# CTRL_MODULE_CORE register map
Vendor: Texas Instruments
Registers are 32-bit, access per field, reset 0x0 unless marked. A register's access mark holds for its fields unless they carry their own. Offsets are as the file gives them; [hi:lo] are bit positions; {n}, {i} and the like mark numbered series; 'fields as' and 'values as' point back to an identical list.

## CTRL_MODULE_CORE (part 8 of 12)
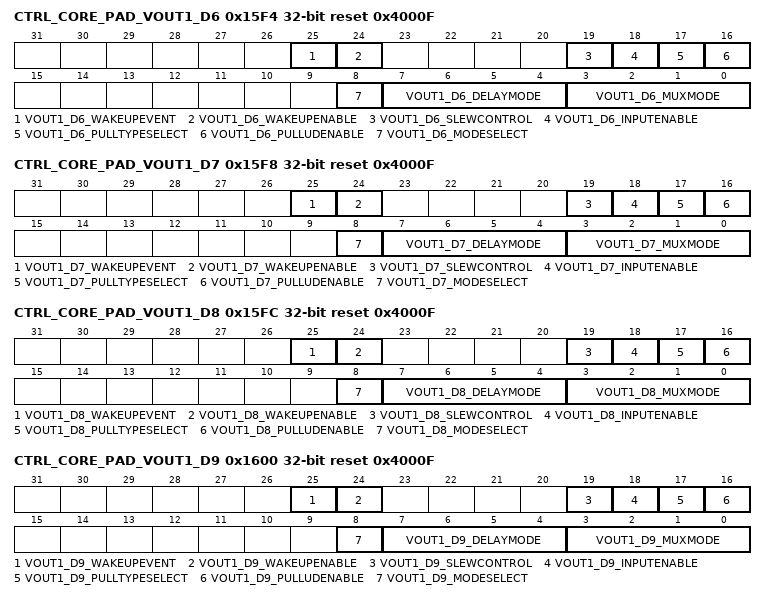
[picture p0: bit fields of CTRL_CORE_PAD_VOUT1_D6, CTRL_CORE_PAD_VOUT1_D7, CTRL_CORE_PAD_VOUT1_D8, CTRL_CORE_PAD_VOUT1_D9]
0x15F4 CTRL_CORE_PAD_VOUT1_D6 reset 0x4000F
  [25] VOUT1_D6_WAKEUPEVENT ro
    0=NOWAKEUP (No wakeup event detected); 1=WAKEUP (Wakeup event detected)
  [24] VOUT1_D6_WAKEUPENABLE rw
    0=DISABLE (Wakeup is disabled); 1=ENABLE (Wakeup is enabled)
  [19] VOUT1_D6_SLEWCONTROL rw
    0=FAST_SLEW (Fast slew is selected); 1=SLOW_SLEW (Slow slew is selected)
  [18] VOUT1_D6_INPUTENABLE rw
    0=DISABLE (Receive mode is disabled); 1=ENABLE (Receive mode is enabled)
  [17] VOUT1_D6_PULLTYPESELECT rw
    0=PULL_DOWN (Pull Down is selected); 1=PULL_UP (Pull Up is selected)
  [16] VOUT1_D6_PULLUDENABLE rw
    0=ENABLE (Enables weak Pull Up/Down); 1=DISABLE (Disables weak Pull Up/Down)
  [8] VOUT1_D6_MODESELECT rw — Selects between the Default IO Timing Mode and a Virtual or Manual IO Timing Mode. Refer to the device Data Manual for definition of the required settings for a given mode of operation. When this bit is 0b1, a Virtual IO Timing Mode can be selected via the DELAYMODE field of this register, as described in, Virtual IO Timing Modes. Manual IO Timing Modes are selected via the procedure described in , Manual IO Timing Modes.
    0=MUX_MODE (Default IO Timing Mode is used); 1=DELAY_MODE (A Virtual or Manual IO Timing Mode is used)
  [7:4] VOUT1_D6_DELAYMODE rw — This bit field selects the Virtual Timing Mode used when the MODESELECT bit is set to 0b1. See, Virtual IO Timing Modes for details.
  [3:0] VOUT1_D6_MUXMODE rw
    0=VOUT1_D6; 2=EMU8; 3=VIN4A_D22; 4=VIN3A_D22; 5=OBS4; 6=OBS20; 10=PR2_EDC_LATCH1_IN; 12=PR2_PRU0_GPI3; 13=PR2_PRU0_GPO3; 14=GPIO8_6; 15=DRIVER OFF
0x15F8 CTRL_CORE_PAD_VOUT1_D7 reset 0x4000F
  [25] VOUT1_D7_WAKEUPEVENT ro
    values as CTRL_CORE_PAD_VOUT1_D6.VOUT1_D6_WAKEUPEVENT
  [24] VOUT1_D7_WAKEUPENABLE rw
    0=DISABLE (Wakeup is disabled); 1=ENABLE (Wakeup is enabled)
  [19] VOUT1_D7_SLEWCONTROL rw
    values as CTRL_CORE_PAD_VOUT1_D6.VOUT1_D6_SLEWCONTROL
  [18] VOUT1_D7_INPUTENABLE rw
    values as CTRL_CORE_PAD_VOUT1_D6.VOUT1_D6_INPUTENABLE
  [17] VOUT1_D7_PULLTYPESELECT rw
    values as CTRL_CORE_PAD_VOUT1_D6.VOUT1_D6_PULLTYPESELECT
  [16] VOUT1_D7_PULLUDENABLE rw
    values as CTRL_CORE_PAD_VOUT1_D6.VOUT1_D6_PULLUDENABLE
  [8] VOUT1_D7_MODESELECT rw — Selects between the Default IO Timing Mode and a Virtual or Manual IO Timing Mode. Refer to the device Data Manual for definition of the required settings for a given mode of operation. When this bit is 0b1, a Virtual IO Timing Mode can be selected via the DELAYMODE field of this register, as described in, Virtual IO Timing Modes. Manual IO Timing Modes are selected via the procedure described in , Manual IO Timing Modes.
    values as CTRL_CORE_PAD_VOUT1_D6.VOUT1_D6_MODESELECT
  [7:4] VOUT1_D7_DELAYMODE rw — This bit field selects the Virtual Timing Mode used when the MODESELECT bit is set to 0b1. See, Virtual IO Timing Modes for details.
  [3:0] VOUT1_D7_MUXMODE rw
    0=VOUT1_D7; 2=EMU9; 3=VIN4A_D23; 4=VIN3A_D23; 10=PR2_EDC_SYNC0_OUT; 12=PR2_PRU0_GPI4; 13=PR2_PRU0_GPO4; 14=GPIO8_7; 15=DRIVER OFF
0x15FC CTRL_CORE_PAD_VOUT1_D8 reset 0x4000F
  [25] VOUT1_D8_WAKEUPEVENT ro
    values as CTRL_CORE_PAD_VOUT1_D6.VOUT1_D6_WAKEUPEVENT
  [24] VOUT1_D8_WAKEUPENABLE rw
    0=DISABLE (Wakeup is disabled); 1=ENABLE (Wakeup is enabled)
  [19] VOUT1_D8_SLEWCONTROL rw
    values as CTRL_CORE_PAD_VOUT1_D6.VOUT1_D6_SLEWCONTROL
  [18] VOUT1_D8_INPUTENABLE rw
    values as CTRL_CORE_PAD_VOUT1_D6.VOUT1_D6_INPUTENABLE
  [17] VOUT1_D8_PULLTYPESELECT rw
    values as CTRL_CORE_PAD_VOUT1_D6.VOUT1_D6_PULLTYPESELECT
  [16] VOUT1_D8_PULLUDENABLE rw
    values as CTRL_CORE_PAD_VOUT1_D6.VOUT1_D6_PULLUDENABLE
  [8] VOUT1_D8_MODESELECT rw — Selects between the Default IO Timing Mode and a Virtual or Manual IO Timing Mode. Refer to the device Data Manual for definition of the required settings for a given mode of operation. When this bit is 0b1, a Virtual IO Timing Mode can be selected via the DELAYMODE field of this register, as described in, Virtual IO Timing Modes. Manual IO Timing Modes are selected via the procedure described in , Manual IO Timing Modes.
    values as CTRL_CORE_PAD_VOUT1_D6.VOUT1_D6_MODESELECT
  [7:4] VOUT1_D8_DELAYMODE rw — This bit field selects the Virtual Timing Mode used when the MODESELECT bit is set to 0b1. See, Virtual IO Timing Modes for details.
  [3:0] VOUT1_D8_MUXMODE rw
    0=VOUT1_D8; 2=UART6_RXD; 3=VIN4A_D8; 4=VIN3A_D8; 10=PR2_EDC_SYNC1_OUT; 12=PR2_PRU0_GPI5; 13=PR2_PRU0_GPO5; 14=GPIO8_8; 15=DRIVER OFF
0x1600 CTRL_CORE_PAD_VOUT1_D9 reset 0x4000F
  [25] VOUT1_D9_WAKEUPEVENT ro
    values as CTRL_CORE_PAD_VOUT1_D6.VOUT1_D6_WAKEUPEVENT
  [24] VOUT1_D9_WAKEUPENABLE rw
    0=DISABLE (Wakeup is disabled); 1=ENABLE (Wakeup is enabled)
  [19] VOUT1_D9_SLEWCONTROL rw
    values as CTRL_CORE_PAD_VOUT1_D6.VOUT1_D6_SLEWCONTROL
  [18] VOUT1_D9_INPUTENABLE rw
    values as CTRL_CORE_PAD_VOUT1_D6.VOUT1_D6_INPUTENABLE
  [17] VOUT1_D9_PULLTYPESELECT rw
    values as CTRL_CORE_PAD_VOUT1_D6.VOUT1_D6_PULLTYPESELECT
  [16] VOUT1_D9_PULLUDENABLE rw
    values as CTRL_CORE_PAD_VOUT1_D6.VOUT1_D6_PULLUDENABLE
  [8] VOUT1_D9_MODESELECT rw — Selects between the Default IO Timing Mode and a Virtual or Manual IO Timing Mode. Refer to the device Data Manual for definition of the required settings for a given mode of operation. When this bit is 0b1, a Virtual IO Timing Mode can be selected via the DELAYMODE field of this register, as described in, Virtual IO Timing Modes. Manual IO Timing Modes are selected via the procedure described in , Manual IO Timing Modes.
    values as CTRL_CORE_PAD_VOUT1_D6.VOUT1_D6_MODESELECT
  [7:4] VOUT1_D9_DELAYMODE rw — This bit field selects the Virtual Timing Mode used when the MODESELECT bit is set to 0b1. See, Virtual IO Timing Modes for details.
  [3:0] VOUT1_D9_MUXMODE rw
    0=VOUT1_D9; 2=UART6_TXD; 3=VIN4A_D9; 4=VIN3A_D9; 10=PR2_EDIO_LATCH_IN; 12=PR2_PRU0_GPI6; 13=PR2_PRU0_GPO6; 14=GPIO8_9; 15=DRIVER OFF
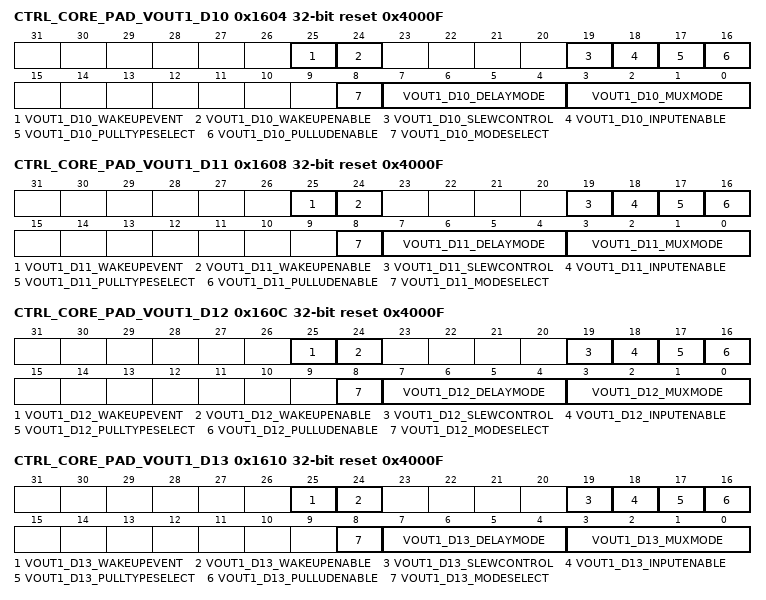
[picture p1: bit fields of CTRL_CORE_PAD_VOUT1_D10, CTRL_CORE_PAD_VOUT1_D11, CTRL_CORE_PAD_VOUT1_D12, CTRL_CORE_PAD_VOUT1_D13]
0x1604 CTRL_CORE_PAD_VOUT1_D10 reset 0x4000F
  [25] VOUT1_D10_WAKEUPEVENT ro
    values as CTRL_CORE_PAD_VOUT1_D6.VOUT1_D6_WAKEUPEVENT
  [24] VOUT1_D10_WAKEUPENABLE rw
    0=DISABLE (Wakeup is disabled); 1=ENABLE (Wakeup is enabled)
  [19] VOUT1_D10_SLEWCONTROL rw
    values as CTRL_CORE_PAD_VOUT1_D6.VOUT1_D6_SLEWCONTROL
  [18] VOUT1_D10_INPUTENABLE rw
    values as CTRL_CORE_PAD_VOUT1_D6.VOUT1_D6_INPUTENABLE
  [17] VOUT1_D10_PULLTYPESELECT rw
    values as CTRL_CORE_PAD_VOUT1_D6.VOUT1_D6_PULLTYPESELECT
  [16] VOUT1_D10_PULLUDENABLE rw
    values as CTRL_CORE_PAD_VOUT1_D6.VOUT1_D6_PULLUDENABLE
  [8] VOUT1_D10_MODESELECT rw — Selects between the Default IO Timing Mode and a Virtual or Manual IO Timing Mode. Refer to the device Data Manual for definition of the required settings for a given mode of operation. When this bit is 0b1, a Virtual IO Timing Mode can be selected via the DELAYMODE field of this register, as described in, Virtual IO Timing Modes. Manual IO Timing Modes are selected via the procedure described in , Manual IO Timing Modes.
    values as CTRL_CORE_PAD_VOUT1_D6.VOUT1_D6_MODESELECT
  [7:4] VOUT1_D10_DELAYMODE rw — This bit field selects the Virtual Timing Mode used when the MODESELECT bit is set to 0b1. See, Virtual IO Timing Modes for details.
  [3:0] VOUT1_D10_MUXMODE rw
    0=VOUT1_D10; 2=EMU3; 3=VIN4A_D10; 4=VIN3A_D10; 5=OBS5; 6=OBS21; 7=OBS_IRQ2; 10=PR2_EDIO_SOF; 12=PR2_PRU0_GPI7; 13=PR2_PRU0_GPO7; 14=GPIO8_10; 15=DRIVER OFF
0x1608 CTRL_CORE_PAD_VOUT1_D11 reset 0x4000F
  [25] VOUT1_D11_WAKEUPEVENT ro
    values as CTRL_CORE_PAD_VOUT1_D6.VOUT1_D6_WAKEUPEVENT
  [24] VOUT1_D11_WAKEUPENABLE rw
    0=DISABLE (Wakeup is disabled); 1=ENABLE (Wakeup is enabled)
  [19] VOUT1_D11_SLEWCONTROL rw
    values as CTRL_CORE_PAD_VOUT1_D6.VOUT1_D6_SLEWCONTROL
  [18] VOUT1_D11_INPUTENABLE rw
    values as CTRL_CORE_PAD_VOUT1_D6.VOUT1_D6_INPUTENABLE
  [17] VOUT1_D11_PULLTYPESELECT rw
    values as CTRL_CORE_PAD_VOUT1_D6.VOUT1_D6_PULLTYPESELECT
  [16] VOUT1_D11_PULLUDENABLE rw
    values as CTRL_CORE_PAD_VOUT1_D6.VOUT1_D6_PULLUDENABLE
  [8] VOUT1_D11_MODESELECT rw — Selects between the Default IO Timing Mode and a Virtual or Manual IO Timing Mode. Refer to the device Data Manual for definition of the required settings for a given mode of operation. When this bit is 0b1, a Virtual IO Timing Mode can be selected via the DELAYMODE field of this register, as described in, Virtual IO Timing Modes. Manual IO Timing Modes are selected via the procedure described in , Manual IO Timing Modes.
    values as CTRL_CORE_PAD_VOUT1_D6.VOUT1_D6_MODESELECT
  [7:4] VOUT1_D11_DELAYMODE rw — This bit field selects the Virtual Timing Mode used when the MODESELECT bit is set to 0b1. See, Virtual IO Timing Modes for details.
  [3:0] VOUT1_D11_MUXMODE rw
    0=VOUT1_D11; 2=EMU10; 3=VIN4A_D11; 4=VIN3A_D11; 5=OBS6; 6=OBS22; 7=OBS_DMARQ2; 10=PR2_UART0_CTS_N; 12=PR2_PRU0_GPI8; 13=PR2_PRU0_GPO8; 14=GPIO8_11; 15=DRIVER OFF
0x160C CTRL_CORE_PAD_VOUT1_D12 reset 0x4000F
  [25] VOUT1_D12_WAKEUPEVENT ro
    values as CTRL_CORE_PAD_VOUT1_D6.VOUT1_D6_WAKEUPEVENT
  [24] VOUT1_D12_WAKEUPENABLE rw
    0=DISABLE (Wakeup is disabled); 1=ENABLE (Wakeup is enabled)
  [19] VOUT1_D12_SLEWCONTROL rw
    values as CTRL_CORE_PAD_VOUT1_D6.VOUT1_D6_SLEWCONTROL
  [18] VOUT1_D12_INPUTENABLE rw
    values as CTRL_CORE_PAD_VOUT1_D6.VOUT1_D6_INPUTENABLE
  [17] VOUT1_D12_PULLTYPESELECT rw
    values as CTRL_CORE_PAD_VOUT1_D6.VOUT1_D6_PULLTYPESELECT
  [16] VOUT1_D12_PULLUDENABLE rw
    values as CTRL_CORE_PAD_VOUT1_D6.VOUT1_D6_PULLUDENABLE
  [8] VOUT1_D12_MODESELECT rw — Selects between the Default IO Timing Mode and a Virtual or Manual IO Timing Mode. Refer to the device Data Manual for definition of the required settings for a given mode of operation. When this bit is 0b1, a Virtual IO Timing Mode can be selected via the DELAYMODE field of this register, as described in, Virtual IO Timing Modes. Manual IO Timing Modes are selected via the procedure described in , Manual IO Timing Modes.
    values as CTRL_CORE_PAD_VOUT1_D6.VOUT1_D6_MODESELECT
  [7:4] VOUT1_D12_DELAYMODE rw — This bit field selects the Virtual Timing Mode used when the MODESELECT bit is set to 0b1. See, Virtual IO Timing Modes for details.
  [3:0] VOUT1_D12_MUXMODE rw
    0=VOUT1_D12; 2=EMU11; 3=VIN4A_D12; 4=VIN3A_D12; 5=OBS7; 6=OBS23; 10=PR2_UART0_RTS_N; 12=PR2_PRU0_GPI9; 13=PR2_PRU0_GPO9; 14=GPIO8_12; 15=DRIVER OFF
0x1610 CTRL_CORE_PAD_VOUT1_D13 reset 0x4000F
  [25] VOUT1_D13_WAKEUPEVENT ro
    values as CTRL_CORE_PAD_VOUT1_D6.VOUT1_D6_WAKEUPEVENT
  [24] VOUT1_D13_WAKEUPENABLE rw
    0=DISABLE (Wakeup is disabled); 1=ENABLE (Wakeup is enabled)
  [19] VOUT1_D13_SLEWCONTROL rw
    values as CTRL_CORE_PAD_VOUT1_D6.VOUT1_D6_SLEWCONTROL
  [18] VOUT1_D13_INPUTENABLE rw
    values as CTRL_CORE_PAD_VOUT1_D6.VOUT1_D6_INPUTENABLE
  [17] VOUT1_D13_PULLTYPESELECT rw
    values as CTRL_CORE_PAD_VOUT1_D6.VOUT1_D6_PULLTYPESELECT
  [16] VOUT1_D13_PULLUDENABLE rw
    values as CTRL_CORE_PAD_VOUT1_D6.VOUT1_D6_PULLUDENABLE
  [8] VOUT1_D13_MODESELECT rw — Selects between the Default IO Timing Mode and a Virtual or Manual IO Timing Mode. Refer to the device Data Manual for definition of the required settings for a given mode of operation. When this bit is 0b1, a Virtual IO Timing Mode can be selected via the DELAYMODE field of this register, as described in, Virtual IO Timing Modes. Manual IO Timing Modes are selected via the procedure described in , Manual IO Timing Modes.
    values as CTRL_CORE_PAD_VOUT1_D6.VOUT1_D6_MODESELECT
  [7:4] VOUT1_D13_DELAYMODE rw — This bit field selects the Virtual Timing Mode used when the MODESELECT bit is set to 0b1. See, Virtual IO Timing Modes for details.
  [3:0] VOUT1_D13_MUXMODE rw
    0=VOUT1_D13; 2=EMU12; 3=VIN4A_D13; 4=VIN3A_D13; 5=OBS8; 6=OBS24; 10=PR2_UART0_RXD; 12=PR2_PRU0_GPI10; 13=PR2_PRU0_GPO10; 14=GPIO8_13; 15=DRIVER OFF
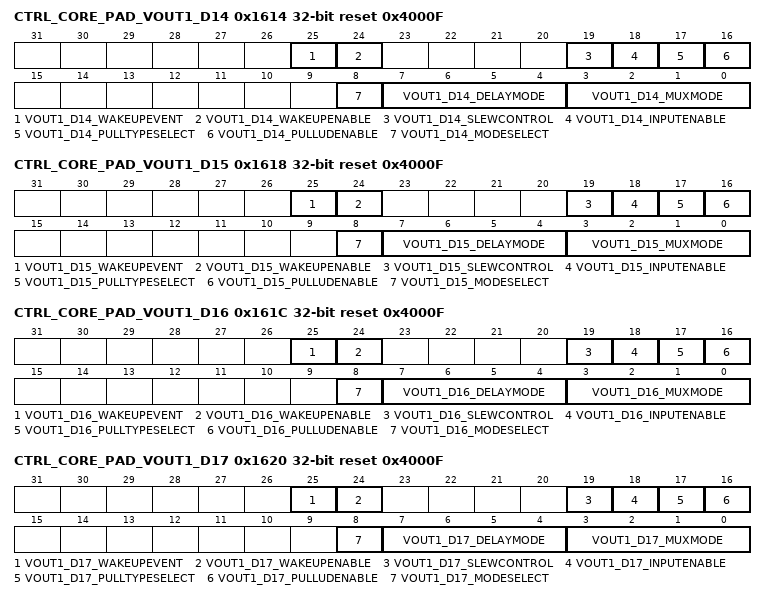
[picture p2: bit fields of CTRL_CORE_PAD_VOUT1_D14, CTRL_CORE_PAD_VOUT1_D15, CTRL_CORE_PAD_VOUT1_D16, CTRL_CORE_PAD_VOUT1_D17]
0x1614 CTRL_CORE_PAD_VOUT1_D14 reset 0x4000F
  [25] VOUT1_D14_WAKEUPEVENT ro
    values as CTRL_CORE_PAD_VOUT1_D6.VOUT1_D6_WAKEUPEVENT
  [24] VOUT1_D14_WAKEUPENABLE rw
    0=DISABLE (Wakeup is disabled); 1=ENABLE (Wakeup is enabled)
  [19] VOUT1_D14_SLEWCONTROL rw
    values as CTRL_CORE_PAD_VOUT1_D6.VOUT1_D6_SLEWCONTROL
  [18] VOUT1_D14_INPUTENABLE rw
    values as CTRL_CORE_PAD_VOUT1_D6.VOUT1_D6_INPUTENABLE
  [17] VOUT1_D14_PULLTYPESELECT rw
    values as CTRL_CORE_PAD_VOUT1_D6.VOUT1_D6_PULLTYPESELECT
  [16] VOUT1_D14_PULLUDENABLE rw
    values as CTRL_CORE_PAD_VOUT1_D6.VOUT1_D6_PULLUDENABLE
  [8] VOUT1_D14_MODESELECT rw — Selects between the Default IO Timing Mode and a Virtual or Manual IO Timing Mode. Refer to the device Data Manual for definition of the required settings for a given mode of operation. When this bit is 0b1, a Virtual IO Timing Mode can be selected via the DELAYMODE field of this register, as described in, Virtual IO Timing Modes. Manual IO Timing Modes are selected via the procedure described in , Manual IO Timing Modes.
    values as CTRL_CORE_PAD_VOUT1_D6.VOUT1_D6_MODESELECT
  [7:4] VOUT1_D14_DELAYMODE rw — This bit field selects the Virtual Timing Mode used when the MODESELECT bit is set to 0b1. See, Virtual IO Timing Modes for details.
  [3:0] VOUT1_D14_MUXMODE rw
    0=VOUT1_D14; 2=EMU13; 3=VIN4A_D14; 4=VIN3A_D14; 5=OBS9; 6=OBS25; 10=PR2_UART0_TXD; 12=PR2_PRU0_GPI11; 13=PR2_PRU0_GPO11; 14=GPIO8_14; 15=DRIVER OFF
0x1618 CTRL_CORE_PAD_VOUT1_D15 reset 0x4000F
  [25] VOUT1_D15_WAKEUPEVENT ro
    values as CTRL_CORE_PAD_VOUT1_D6.VOUT1_D6_WAKEUPEVENT
  [24] VOUT1_D15_WAKEUPENABLE rw
    0=DISABLE (Wakeup is disabled); 1=ENABLE (Wakeup is enabled)
  [19] VOUT1_D15_SLEWCONTROL rw
    values as CTRL_CORE_PAD_VOUT1_D6.VOUT1_D6_SLEWCONTROL
  [18] VOUT1_D15_INPUTENABLE rw
    values as CTRL_CORE_PAD_VOUT1_D6.VOUT1_D6_INPUTENABLE
  [17] VOUT1_D15_PULLTYPESELECT rw
    values as CTRL_CORE_PAD_VOUT1_D6.VOUT1_D6_PULLTYPESELECT
  [16] VOUT1_D15_PULLUDENABLE rw
    values as CTRL_CORE_PAD_VOUT1_D6.VOUT1_D6_PULLUDENABLE
  [8] VOUT1_D15_MODESELECT rw — Selects between the Default IO Timing Mode and a Virtual or Manual IO Timing Mode. Refer to the device Data Manual for definition of the required settings for a given mode of operation. When this bit is 0b1, a Virtual IO Timing Mode can be selected via the DELAYMODE field of this register, as described in, Virtual IO Timing Modes. Manual IO Timing Modes are selected via the procedure described in , Manual IO Timing Modes.
    values as CTRL_CORE_PAD_VOUT1_D6.VOUT1_D6_MODESELECT
  [7:4] VOUT1_D15_DELAYMODE rw — This bit field selects the Virtual Timing Mode used when the MODESELECT bit is set to 0b1. See, Virtual IO Timing Modes for details.
  [3:0] VOUT1_D15_MUXMODE rw
    0=VOUT1_D15; 2=EMU14; 3=VIN4A_D15; 4=VIN3A_D15; 5=OBS10; 6=OBS26; 10=PR2_ECAP0_ECAP_CAPIN_APWM_O; 12=PR2_PRU0_GPI12; 13=PR2_PRU0_GPO12; 14=GPIO8_15; 15=DRIVER OFF
0x161C CTRL_CORE_PAD_VOUT1_D16 reset 0x4000F
  [25] VOUT1_D16_WAKEUPEVENT ro
    values as CTRL_CORE_PAD_VOUT1_D6.VOUT1_D6_WAKEUPEVENT
  [24] VOUT1_D16_WAKEUPENABLE rw
    0=DISABLE (Wakeup is disabled); 1=ENABLE (Wakeup is enabled)
  [19] VOUT1_D16_SLEWCONTROL rw
    values as CTRL_CORE_PAD_VOUT1_D6.VOUT1_D6_SLEWCONTROL
  [18] VOUT1_D16_INPUTENABLE rw
    values as CTRL_CORE_PAD_VOUT1_D6.VOUT1_D6_INPUTENABLE
  [17] VOUT1_D16_PULLTYPESELECT rw
    values as CTRL_CORE_PAD_VOUT1_D6.VOUT1_D6_PULLTYPESELECT
  [16] VOUT1_D16_PULLUDENABLE rw
    values as CTRL_CORE_PAD_VOUT1_D6.VOUT1_D6_PULLUDENABLE
  [8] VOUT1_D16_MODESELECT rw — Selects between the Default IO Timing Mode and a Virtual or Manual IO Timing Mode. Refer to the device Data Manual for definition of the required settings for a given mode of operation. When this bit is 0b1, a Virtual IO Timing Mode can be selected via the DELAYMODE field of this register, as described in, Virtual IO Timing Modes. Manual IO Timing Modes are selected via the procedure described in , Manual IO Timing Modes.
    values as CTRL_CORE_PAD_VOUT1_D6.VOUT1_D6_MODESELECT
  [7:4] VOUT1_D16_DELAYMODE rw — This bit field selects the Virtual Timing Mode used when the MODESELECT bit is set to 0b1. See, Virtual IO Timing Modes for details.
  [3:0] VOUT1_D16_MUXMODE rw
    0=VOUT1_D16; 2=UART7_RXD; 3=VIN4A_D0; 4=VIN3A_D0; 10=PR2_EDIO_DATA_IN0; 11=PR2_EDIO_DATA_OUT0; 12=PR2_PRU0_GPI13; 13=PR2_PRU0_GPO13; 14=GPIO8_16; 15=DRIVER OFF
0x1620 CTRL_CORE_PAD_VOUT1_D17 reset 0x4000F
  [25] VOUT1_D17_WAKEUPEVENT ro
    values as CTRL_CORE_PAD_VOUT1_D6.VOUT1_D6_WAKEUPEVENT
  [24] VOUT1_D17_WAKEUPENABLE rw
    0=DISABLE (Wakeup is disabled); 1=ENABLE (Wakeup is enabled)
  [19] VOUT1_D17_SLEWCONTROL rw
    values as CTRL_CORE_PAD_VOUT1_D6.VOUT1_D6_SLEWCONTROL
  [18] VOUT1_D17_INPUTENABLE rw
    values as CTRL_CORE_PAD_VOUT1_D6.VOUT1_D6_INPUTENABLE
  [17] VOUT1_D17_PULLTYPESELECT rw
    values as CTRL_CORE_PAD_VOUT1_D6.VOUT1_D6_PULLTYPESELECT
  [16] VOUT1_D17_PULLUDENABLE rw
    values as CTRL_CORE_PAD_VOUT1_D6.VOUT1_D6_PULLUDENABLE
  [8] VOUT1_D17_MODESELECT rw — Selects between the Default IO Timing Mode and a Virtual or Manual IO Timing Mode. Refer to the device Data Manual for definition of the required settings for a given mode of operation. When this bit is 0b1, a Virtual IO Timing Mode can be selected via the DELAYMODE field of this register, as described in, Virtual IO Timing Modes. Manual IO Timing Modes are selected via the procedure described in , Manual IO Timing Modes.
    values as CTRL_CORE_PAD_VOUT1_D6.VOUT1_D6_MODESELECT
  [7:4] VOUT1_D17_DELAYMODE rw — This bit field selects the Virtual Timing Mode used when the MODESELECT bit is set to 0b1. See, Virtual IO Timing Modes for details.
  [3:0] VOUT1_D17_MUXMODE rw
    0=VOUT1_D17; 2=UART7_TXD; 3=VIN4A_D1; 4=VIN3A_D1; 10=PR2_EDIO_DATA_IN1; 11=PR2_EDIO_DATA_OUT1; 12=PR2_PRU0_GPI14; 13=PR2_PRU0_GPO14; 14=GPIO8_17; 15=DRIVER OFF
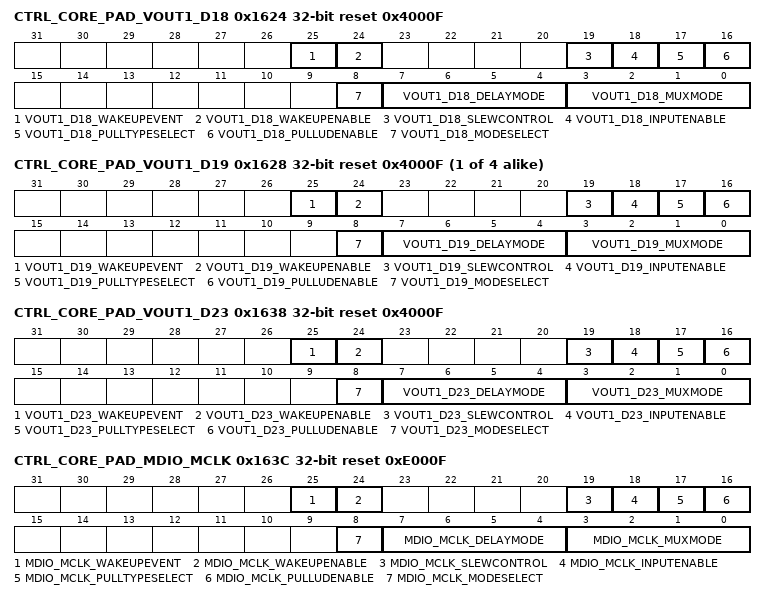
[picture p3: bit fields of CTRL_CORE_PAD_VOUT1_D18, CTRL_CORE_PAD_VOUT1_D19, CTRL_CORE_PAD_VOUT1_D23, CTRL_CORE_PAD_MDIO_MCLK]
0x1624 CTRL_CORE_PAD_VOUT1_D18 reset 0x4000F
  [25] VOUT1_D18_WAKEUPEVENT ro
    values as CTRL_CORE_PAD_VOUT1_D6.VOUT1_D6_WAKEUPEVENT
  [24] VOUT1_D18_WAKEUPENABLE rw
    0=DISABLE (Wakeup is disabled); 1=ENABLE (Wakeup is enabled)
  [19] VOUT1_D18_SLEWCONTROL rw
    values as CTRL_CORE_PAD_VOUT1_D6.VOUT1_D6_SLEWCONTROL
  [18] VOUT1_D18_INPUTENABLE rw
    values as CTRL_CORE_PAD_VOUT1_D6.VOUT1_D6_INPUTENABLE
  [17] VOUT1_D18_PULLTYPESELECT rw
    values as CTRL_CORE_PAD_VOUT1_D6.VOUT1_D6_PULLTYPESELECT
  [16] VOUT1_D18_PULLUDENABLE rw
    values as CTRL_CORE_PAD_VOUT1_D6.VOUT1_D6_PULLUDENABLE
  [8] VOUT1_D18_MODESELECT rw — Selects between the Default IO Timing Mode and a Virtual or Manual IO Timing Mode. Refer to the device Data Manual for definition of the required settings for a given mode of operation. When this bit is 0b1, a Virtual IO Timing Mode can be selected via the DELAYMODE field of this register, as described in, Virtual IO Timing Modes. Manual IO Timing Modes are selected via the procedure described in , Manual IO Timing Modes.
    values as CTRL_CORE_PAD_VOUT1_D6.VOUT1_D6_MODESELECT
  [7:4] VOUT1_D18_DELAYMODE rw — This bit field selects the Virtual Timing Mode used when the MODESELECT bit is set to 0b1. See, Virtual IO Timing Modes for details.
  [3:0] VOUT1_D18_MUXMODE rw
    0=VOUT1_D18; 2=EMU4; 3=VIN4A_D2; 4=VIN3A_D2; 5=OBS11; 6=OBS27; 10=PR2_EDIO_DATA_IN2; 11=PR2_EDIO_DATA_OUT2; 12=PR2_PRU0_GPI15; 13=PR2_PRU0_GPO15; 14=GPIO8_18; 15=DRIVER OFF
{0x15DC+4i} CTRL_CORE_PAD_VOUT1_D{i} reset 0x4000F (i=19..22)
  [25] VOUT1_D{i}_WAKEUPEVENT ro
    values as CTRL_CORE_PAD_VOUT1_D6.VOUT1_D6_WAKEUPEVENT
  [24] VOUT1_D{i}_WAKEUPENABLE rw
    0=DISABLE (Wakeup is disabled); 1=ENABLE (Wakeup is enabled)
  [19] VOUT1_D{i}_SLEWCONTROL rw
    values as CTRL_CORE_PAD_VOUT1_D6.VOUT1_D6_SLEWCONTROL
  [18] VOUT1_D{i}_INPUTENABLE rw
    values as CTRL_CORE_PAD_VOUT1_D6.VOUT1_D6_INPUTENABLE
  [17] VOUT1_D{i}_PULLTYPESELECT rw
    values as CTRL_CORE_PAD_VOUT1_D6.VOUT1_D6_PULLTYPESELECT
  [16] VOUT1_D{i}_PULLUDENABLE rw
    values as CTRL_CORE_PAD_VOUT1_D6.VOUT1_D6_PULLUDENABLE
  [8] VOUT1_D{i}_MODESELECT rw — Selects between the Default IO Timing Mode and a Virtual or Manual IO Timing Mode. Refer to the device Data Manual for definition of the required settings for a given mode of operation. When this bit is 0b1, a Virtual IO Timing Mode can be selected via the DELAYMODE field of this register, as described in, Virtual IO Timing Modes. Manual IO Timing Modes are selected via the procedure described in , Manual IO Timing Modes.
    values as CTRL_CORE_PAD_VOUT1_D6.VOUT1_D6_MODESELECT
  [7:4] VOUT1_D{i}_DELAYMODE rw — This bit field selects the Virtual Timing Mode used when the MODESELECT bit is set to 0b1. See, Virtual IO Timing Modes for details.
  [3:0] VOUT1_D{i}_MUXMODE rw
    0=VOUT1_D{i}; 2=EMU{i-4}; 3=VIN4A_D{i-16}; 4=VIN3A_D{i-16}; 5=OBS{i-7}; 6=OBS{i+9}; 10=PR2_EDIO_DATA_IN{i-16}; 11=PR2_EDIO_DATA_OUT{i-16}; 12=PR2_PRU0_GPI{i-3}; 13=PR2_PRU0_GPO{i-3}; 14=GPIO8_{i}; 15=DRIVER OFF
0x1638 CTRL_CORE_PAD_VOUT1_D23 reset 0x4000F
  [25] VOUT1_D23_WAKEUPEVENT ro
    values as CTRL_CORE_PAD_VOUT1_D6.VOUT1_D6_WAKEUPEVENT
  [24] VOUT1_D23_WAKEUPENABLE rw
    0=DISABLE (Wakeup is disabled); 1=ENABLE (Wakeup is enabled)
  [19] VOUT1_D23_SLEWCONTROL rw
    values as CTRL_CORE_PAD_VOUT1_D6.VOUT1_D6_SLEWCONTROL
  [18] VOUT1_D23_INPUTENABLE rw
    values as CTRL_CORE_PAD_VOUT1_D6.VOUT1_D6_INPUTENABLE
  [17] VOUT1_D23_PULLTYPESELECT rw
    values as CTRL_CORE_PAD_VOUT1_D6.VOUT1_D6_PULLTYPESELECT
  [16] VOUT1_D23_PULLUDENABLE rw
    values as CTRL_CORE_PAD_VOUT1_D6.VOUT1_D6_PULLUDENABLE
  [8] VOUT1_D23_MODESELECT rw — Selects between the Default IO Timing Mode and a Virtual or Manual IO Timing Mode. Refer to the device Data Manual for definition of the required settings for a given mode of operation. When this bit is 0b1, a Virtual IO Timing Mode can be selected via the DELAYMODE field of this register, as described in, Virtual IO Timing Modes. Manual IO Timing Modes are selected via the procedure described in , Manual IO Timing Modes.
    values as CTRL_CORE_PAD_VOUT1_D6.VOUT1_D6_MODESELECT
  [7:4] VOUT1_D23_DELAYMODE rw — This bit field selects the Virtual Timing Mode used when the MODESELECT bit is set to 0b1. See, Virtual IO Timing Modes for details.
  [3:0] VOUT1_D23_MUXMODE rw
    0=VOUT1_D23; 2=EMU19; 3=VIN4A_D7; 4=VIN3A_D7; 8=SPI3_CS3; 10=PR2_EDIO_DATA_IN7; 11=PR2_EDIO_DATA_OUT7; 12=PR2_PRU0_GPI20; 13=PR2_PRU0_GPO20; 14=GPIO8_23; 15=DRIVER OFF
0x163C CTRL_CORE_PAD_MDIO_MCLK reset 0xE000F
  [25] MDIO_MCLK_WAKEUPEVENT ro
    values as CTRL_CORE_PAD_VOUT1_D6.VOUT1_D6_WAKEUPEVENT
  [24] MDIO_MCLK_WAKEUPENABLE rw
    0=DISABLE (Wakeup is disabled); 1=ENABLE (Wakeup is enabled)
  [19] MDIO_MCLK_SLEWCONTROL rw
    values as CTRL_CORE_PAD_VOUT1_D6.VOUT1_D6_SLEWCONTROL
  [18] MDIO_MCLK_INPUTENABLE rw
    values as CTRL_CORE_PAD_VOUT1_D6.VOUT1_D6_INPUTENABLE
  [17] MDIO_MCLK_PULLTYPESELECT rw
    values as CTRL_CORE_PAD_VOUT1_D6.VOUT1_D6_PULLTYPESELECT
  [16] MDIO_MCLK_PULLUDENABLE rw
    values as CTRL_CORE_PAD_VOUT1_D6.VOUT1_D6_PULLUDENABLE
  [8] MDIO_MCLK_MODESELECT rw — Selects between the Default IO Timing Mode and a Virtual or Manual IO Timing Mode. Refer to the device Data Manual for definition of the required settings for a given mode of operation. When this bit is 0b1, a Virtual IO Timing Mode can be selected via the DELAYMODE field of this register, as described in, Virtual IO Timing Modes. Manual IO Timing Modes are selected via the procedure described in , Manual IO Timing Modes.
    values as CTRL_CORE_PAD_VOUT1_D6.VOUT1_D6_MODESELECT
  [7:4] MDIO_MCLK_DELAYMODE rw — This bit field selects the Virtual Timing Mode used when the MODESELECT bit is set to 0b1. See, Virtual IO Timing Modes for details.
  [3:0] MDIO_MCLK_MUXMODE rw
    0=MDIO_MCLK; 1=UART3_RTSN; 3=MII0_COL; 4=VIN2A_CLK0; 5=VIN4B_CLK1; 11=PR1_MII0_COL; 12=PR2_PRU1_GPI0; 13=PR2_PRU1_GPO0; 14=GPIO5_15; 15=DRIVER OFF
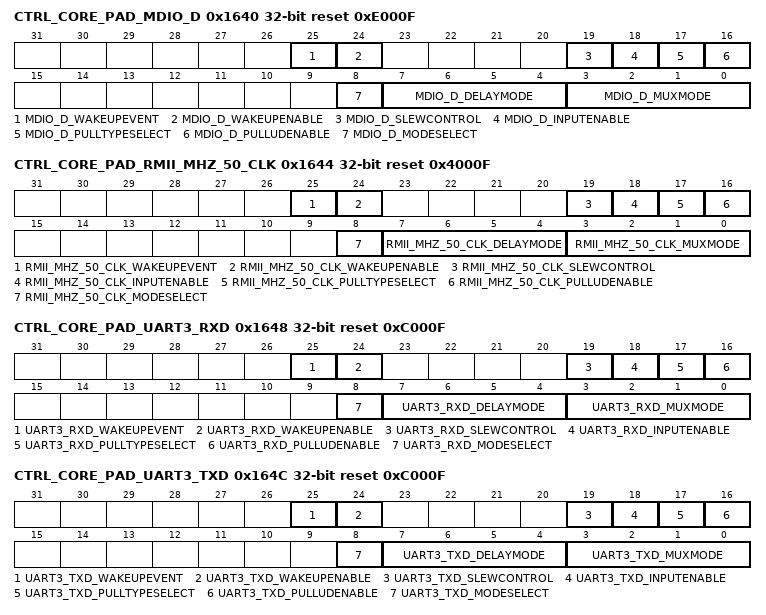
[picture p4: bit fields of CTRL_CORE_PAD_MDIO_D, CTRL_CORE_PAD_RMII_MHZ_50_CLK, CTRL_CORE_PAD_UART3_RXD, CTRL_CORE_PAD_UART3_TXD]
0x1640 CTRL_CORE_PAD_MDIO_D reset 0xE000F
  [25] MDIO_D_WAKEUPEVENT ro
    values as CTRL_CORE_PAD_VOUT1_D6.VOUT1_D6_WAKEUPEVENT
  [24] MDIO_D_WAKEUPENABLE rw
    0=DISABLE (Wakeup is disabled); 1=ENABLE (Wakeup is enabled)
  [19] MDIO_D_SLEWCONTROL rw
    values as CTRL_CORE_PAD_VOUT1_D6.VOUT1_D6_SLEWCONTROL
  [18] MDIO_D_INPUTENABLE rw
    values as CTRL_CORE_PAD_VOUT1_D6.VOUT1_D6_INPUTENABLE
  [17] MDIO_D_PULLTYPESELECT rw
    values as CTRL_CORE_PAD_VOUT1_D6.VOUT1_D6_PULLTYPESELECT
  [16] MDIO_D_PULLUDENABLE rw
    values as CTRL_CORE_PAD_VOUT1_D6.VOUT1_D6_PULLUDENABLE
  [8] MDIO_D_MODESELECT rw — Selects between the Default IO Timing Mode and a Virtual or Manual IO Timing Mode. Refer to the device Data Manual for definition of the required settings for a given mode of operation. When this bit is 0b1, a Virtual IO Timing Mode can be selected via the DELAYMODE field of this register, as described in, Virtual IO Timing Modes. Manual IO Timing Modes are selected via the procedure described in , Manual IO Timing Modes.
    values as CTRL_CORE_PAD_VOUT1_D6.VOUT1_D6_MODESELECT
  [7:4] MDIO_D_DELAYMODE rw — This bit field selects the Virtual Timing Mode used when the MODESELECT bit is set to 0b1. See, Virtual IO Timing Modes for details.
  [3:0] MDIO_D_MUXMODE rw
    0=MDIO_D; 1=UART3_CTSN; 3=MII0_TXER; 4=VIN2A_D0; 5=VIN4B_D0; 11=PR1_MII0_RXLINK; 12=PR2_PRU1_GPI1; 13=PR2_PRU1_GPO1; 14=GPIO5_16; 15=DRIVER OFF
0x1644 CTRL_CORE_PAD_RMII_MHZ_50_CLK reset 0x4000F
  [25] RMII_MHZ_50_CLK_WAKEUPEVENT ro
    values as CTRL_CORE_PAD_VOUT1_D6.VOUT1_D6_WAKEUPEVENT
  [24] RMII_MHZ_50_CLK_WAKEUPENABLE rw
    0=DISABLE (Wakeup is disabled); 1=ENABLE (Wakeup is enabled)
  [19] RMII_MHZ_50_CLK_SLEWCONTROL rw
    values as CTRL_CORE_PAD_VOUT1_D6.VOUT1_D6_SLEWCONTROL
  [18] RMII_MHZ_50_CLK_INPUTENABLE rw
    values as CTRL_CORE_PAD_VOUT1_D6.VOUT1_D6_INPUTENABLE
  [17] RMII_MHZ_50_CLK_PULLTYPESELECT rw
    values as CTRL_CORE_PAD_VOUT1_D6.VOUT1_D6_PULLTYPESELECT
  [16] RMII_MHZ_50_CLK_PULLUDENABLE rw
    values as CTRL_CORE_PAD_VOUT1_D6.VOUT1_D6_PULLUDENABLE
  [8] RMII_MHZ_50_CLK_MODESELECT rw — Selects between the Default IO Timing Mode and a Virtual or Manual IO Timing Mode. Refer to the device Data Manual for definition of the required settings for a given mode of operation. When this bit is 0b1, a Virtual IO Timing Mode can be selected via the DELAYMODE field of this register, as described in, Virtual IO Timing Modes. Manual IO Timing Modes are selected via the procedure described in , Manual IO Timing Modes.
    values as CTRL_CORE_PAD_VOUT1_D6.VOUT1_D6_MODESELECT
  [7:4] RMII_MHZ_50_CLK_DELAYMODE rw — This bit field selects the Virtual Timing Mode used when the MODESELECT bit is set to 0b1. See, Virtual IO Timing Modes for details.
  [3:0] RMII_MHZ_50_CLK_MUXMODE rw
    0=RMII_MHZ_50_CLK; 4=VIN2A_D11; 12=PR2_PRU1_GPI2; 13=PR2_PRU1_GPO2; 14=GPIO5_17; 15=DRIVER OFF
0x1648 CTRL_CORE_PAD_UART3_RXD reset 0xC000F
  [25] UART3_RXD_WAKEUPEVENT ro
    values as CTRL_CORE_PAD_VOUT1_D6.VOUT1_D6_WAKEUPEVENT
  [24] UART3_RXD_WAKEUPENABLE rw
    0=DISABLE (Wakeup is disabled); 1=ENABLE (Wakeup is enabled)
  [19] UART3_RXD_SLEWCONTROL rw
    values as CTRL_CORE_PAD_VOUT1_D6.VOUT1_D6_SLEWCONTROL
  [18] UART3_RXD_INPUTENABLE rw
    values as CTRL_CORE_PAD_VOUT1_D6.VOUT1_D6_INPUTENABLE
  [17] UART3_RXD_PULLTYPESELECT rw
    values as CTRL_CORE_PAD_VOUT1_D6.VOUT1_D6_PULLTYPESELECT
  [16] UART3_RXD_PULLUDENABLE rw
    values as CTRL_CORE_PAD_VOUT1_D6.VOUT1_D6_PULLUDENABLE
  [8] UART3_RXD_MODESELECT rw — Selects between the Default IO Timing Mode and a Virtual or Manual IO Timing Mode. Refer to the device Data Manual for definition of the required settings for a given mode of operation. When this bit is 0b1, a Virtual IO Timing Mode can be selected via the DELAYMODE field of this register, as described in, Virtual IO Timing Modes. Manual IO Timing Modes are selected via the procedure described in , Manual IO Timing Modes.
    values as CTRL_CORE_PAD_VOUT1_D6.VOUT1_D6_MODESELECT
  [7:4] UART3_RXD_DELAYMODE rw — This bit field selects the Virtual Timing Mode used when the MODESELECT bit is set to 0b1. See, Virtual IO Timing Modes for details.
  [3:0] UART3_RXD_MUXMODE rw
    0=UART3_RXD; 2=RMII1_CRS; 3=MII0_RXDV; 4=VIN2A_D1; 5=VIN4B_D1; 7=SPI3_SCLK; 11=PR1_MII0_RXDV; 12=PR2_PRU1_GPI3; 13=PR2_PRU1_GPO3; 14=GPIO5_18; 15=DRIVER OFF
0x164C CTRL_CORE_PAD_UART3_TXD reset 0xC000F
  [25] UART3_TXD_WAKEUPEVENT ro
    values as CTRL_CORE_PAD_VOUT1_D6.VOUT1_D6_WAKEUPEVENT
  [24] UART3_TXD_WAKEUPENABLE rw
    0=DISABLE (Wakeup is disabled); 1=ENABLE (Wakeup is enabled)
  [19] UART3_TXD_SLEWCONTROL rw
    values as CTRL_CORE_PAD_VOUT1_D6.VOUT1_D6_SLEWCONTROL
  [18] UART3_TXD_INPUTENABLE rw
    values as CTRL_CORE_PAD_VOUT1_D6.VOUT1_D6_INPUTENABLE
  [17] UART3_TXD_PULLTYPESELECT rw
    values as CTRL_CORE_PAD_VOUT1_D6.VOUT1_D6_PULLTYPESELECT
  [16] UART3_TXD_PULLUDENABLE rw
    values as CTRL_CORE_PAD_VOUT1_D6.VOUT1_D6_PULLUDENABLE
  [8] UART3_TXD_MODESELECT rw — Selects between the Default IO Timing Mode and a Virtual or Manual IO Timing Mode. Refer to the device Data Manual for definition of the required settings for a given mode of operation. When this bit is 0b1, a Virtual IO Timing Mode can be selected via the DELAYMODE field of this register, as described in, Virtual IO Timing Modes. Manual IO Timing Modes are selected via the procedure described in , Manual IO Timing Modes.
    values as CTRL_CORE_PAD_VOUT1_D6.VOUT1_D6_MODESELECT
  [7:4] UART3_TXD_DELAYMODE rw — This bit field selects the Virtual Timing Mode used when the MODESELECT bit is set to 0b1. See, Virtual IO Timing Modes for details.
  [3:0] UART3_TXD_MUXMODE rw
    0=UART3_TXD; 2=RMII1_RXER; 3=MII0_RXCLK; 4=VIN2A_D2; 5=VIN4B_D2; 7=SPI3_D1; 8=SPI4_CS1; 11=PR1_MII_MR0_CLK; 12=PR2_PRU1_GPI4; 13=PR2_PRU1_GPO4; 14=GPIO5_19; 15=DRIVER OFF
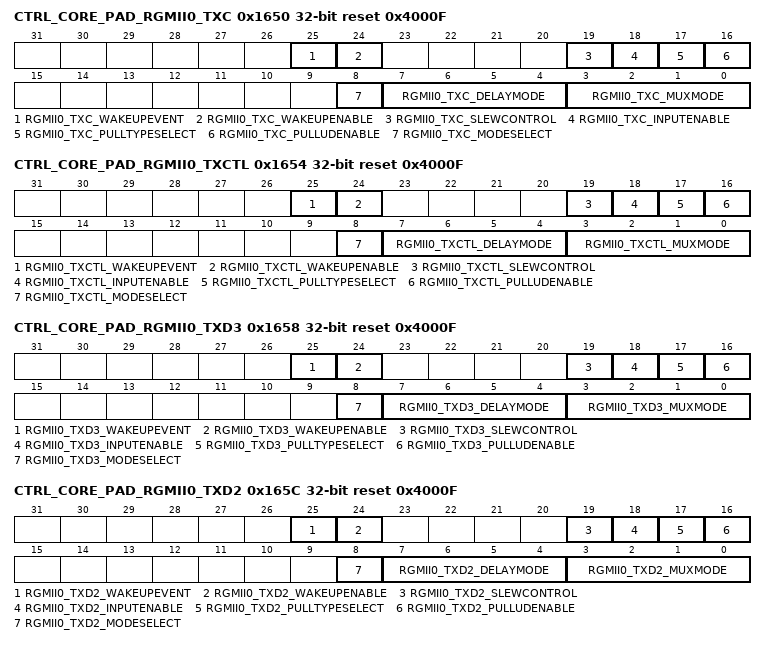
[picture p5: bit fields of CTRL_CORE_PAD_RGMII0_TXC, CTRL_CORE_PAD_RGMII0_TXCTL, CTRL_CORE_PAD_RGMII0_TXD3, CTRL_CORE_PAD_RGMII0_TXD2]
0x1650 CTRL_CORE_PAD_RGMII0_TXC reset 0x4000F
  [25] RGMII0_TXC_WAKEUPEVENT ro
    values as CTRL_CORE_PAD_VOUT1_D6.VOUT1_D6_WAKEUPEVENT
  [24] RGMII0_TXC_WAKEUPENABLE rw
    0=DISABLE (Wakeup is disabled); 1=ENABLE (Wakeup is enabled)
  [19] RGMII0_TXC_SLEWCONTROL rw
    values as CTRL_CORE_PAD_VOUT1_D6.VOUT1_D6_SLEWCONTROL
  [18] RGMII0_TXC_INPUTENABLE rw
    values as CTRL_CORE_PAD_VOUT1_D6.VOUT1_D6_INPUTENABLE
  [17] RGMII0_TXC_PULLTYPESELECT rw
    values as CTRL_CORE_PAD_VOUT1_D6.VOUT1_D6_PULLTYPESELECT
  [16] RGMII0_TXC_PULLUDENABLE rw
    values as CTRL_CORE_PAD_VOUT1_D6.VOUT1_D6_PULLUDENABLE
  [8] RGMII0_TXC_MODESELECT rw — Selects between the Default IO Timing Mode and a Virtual or Manual IO Timing Mode. Refer to the device Data Manual for definition of the required settings for a given mode of operation. When this bit is 0b1, a Virtual IO Timing Mode can be selected via the DELAYMODE field of this register, as described in, Virtual IO Timing Modes. Manual IO Timing Modes are selected via the procedure described in , Manual IO Timing Modes.
    values as CTRL_CORE_PAD_VOUT1_D6.VOUT1_D6_MODESELECT
  [7:4] RGMII0_TXC_DELAYMODE rw — This bit field selects the Virtual Timing Mode used when the MODESELECT bit is set to 0b1. See, Virtual IO Timing Modes for details.
  [3:0] RGMII0_TXC_MUXMODE rw
    0=RGMII0_TXC; 1=UART3_CTSN; 2=RMII1_RXD1; 3=MII0_RXD3; 4=VIN2A_D3; 5=VIN4B_D3; 7=SPI3_D0; 8=SPI4_CS2; 11=PR1_MII0_RXD3; 12=PR2_PRU1_GPI5; 13=PR2_PRU1_GPO5; 14=GPIO5_20; 15=DRIVER OFF
0x1654 CTRL_CORE_PAD_RGMII0_TXCTL reset 0x4000F
  [25] RGMII0_TXCTL_WAKEUPEVENT ro
    values as CTRL_CORE_PAD_VOUT1_D6.VOUT1_D6_WAKEUPEVENT
  [24] RGMII0_TXCTL_WAKEUPENABLE rw
    0=DISABLE (Wakeup is disabled); 1=ENABLE (Wakeup is enabled)
  [19] RGMII0_TXCTL_SLEWCONTROL rw
    values as CTRL_CORE_PAD_VOUT1_D6.VOUT1_D6_SLEWCONTROL
  [18] RGMII0_TXCTL_INPUTENABLE rw
    values as CTRL_CORE_PAD_VOUT1_D6.VOUT1_D6_INPUTENABLE
  [17] RGMII0_TXCTL_PULLTYPESELECT rw
    values as CTRL_CORE_PAD_VOUT1_D6.VOUT1_D6_PULLTYPESELECT
  [16] RGMII0_TXCTL_PULLUDENABLE rw
    values as CTRL_CORE_PAD_VOUT1_D6.VOUT1_D6_PULLUDENABLE
  [8] RGMII0_TXCTL_MODESELECT rw — Selects between the Default IO Timing Mode and a Virtual or Manual IO Timing Mode. Refer to the device Data Manual for definition of the required settings for a given mode of operation. When this bit is 0b1, a Virtual IO Timing Mode can be selected via the DELAYMODE field of this register, as described in, Virtual IO Timing Modes. Manual IO Timing Modes are selected via the procedure described in , Manual IO Timing Modes.
    values as CTRL_CORE_PAD_VOUT1_D6.VOUT1_D6_MODESELECT
  [7:4] RGMII0_TXCTL_DELAYMODE rw — This bit field selects the Virtual Timing Mode used when the MODESELECT bit is set to 0b1. See, Virtual IO Timing Modes for details.
  [3:0] RGMII0_TXCTL_MUXMODE rw
    0=RGMII0_TXCTL; 1=UART3_RTSN; 2=RMII1_RXD0; 3=MII0_RXD2; 4=VIN2A_D4; 5=VIN4B_D4; 7=SPI3_CS0; 8=SPI4_CS3; 11=PR1_MII0_RXD2; 12=PR2_PRU1_GPI6; 13=PR2_PRU1_GPO6; 14=GPIO5_21; 15=DRIVER OFF
0x1658 CTRL_CORE_PAD_RGMII0_TXD3 reset 0x4000F
  [25] RGMII0_TXD3_WAKEUPEVENT ro
    values as CTRL_CORE_PAD_VOUT1_D6.VOUT1_D6_WAKEUPEVENT
  [24] RGMII0_TXD3_WAKEUPENABLE rw
    0=DISABLE (Wakeup is disabled); 1=ENABLE (Wakeup is enabled)
  [19] RGMII0_TXD3_SLEWCONTROL rw
    values as CTRL_CORE_PAD_VOUT1_D6.VOUT1_D6_SLEWCONTROL
  [18] RGMII0_TXD3_INPUTENABLE rw
    values as CTRL_CORE_PAD_VOUT1_D6.VOUT1_D6_INPUTENABLE
  [17] RGMII0_TXD3_PULLTYPESELECT rw
    values as CTRL_CORE_PAD_VOUT1_D6.VOUT1_D6_PULLTYPESELECT
  [16] RGMII0_TXD3_PULLUDENABLE rw
    values as CTRL_CORE_PAD_VOUT1_D6.VOUT1_D6_PULLUDENABLE
  [8] RGMII0_TXD3_MODESELECT rw — Selects between the Default IO Timing Mode and a Virtual or Manual IO Timing Mode. Refer to the device Data Manual for definition of the required settings for a given mode of operation. When this bit is 0b1, a Virtual IO Timing Mode can be selected via the DELAYMODE field of this register, as described in, Virtual IO Timing Modes. Manual IO Timing Modes are selected via the procedure described in , Manual IO Timing Modes.
    values as CTRL_CORE_PAD_VOUT1_D6.VOUT1_D6_MODESELECT
  [7:4] RGMII0_TXD3_DELAYMODE rw — This bit field selects the Virtual Timing Mode used when the MODESELECT bit is set to 0b1. See, Virtual IO Timing Modes for details.
  [3:0] RGMII0_TXD3_MUXMODE rw
    0=RGMII0_TXD3; 1=RMII0_CRS; 3=MII0_CRS; 4=VIN2A_DE0; 5=VIN4B_DE1; 7=SPI4_SCLK; 8=UART4_RXD; 11=PR1_MII0_CRS; 12=PR2_PRU1_GPI7; 13=PR2_PRU1_GPO7; 14=GPIO5_22; 15=DRIVER OFF
0x165C CTRL_CORE_PAD_RGMII0_TXD2 reset 0x4000F
  [25] RGMII0_TXD2_WAKEUPEVENT ro
    values as CTRL_CORE_PAD_VOUT1_D6.VOUT1_D6_WAKEUPEVENT
  [24] RGMII0_TXD2_WAKEUPENABLE rw
    0=DISABLE (Wakeup is disabled); 1=ENABLE (Wakeup is enabled)
  [19] RGMII0_TXD2_SLEWCONTROL rw
    values as CTRL_CORE_PAD_VOUT1_D6.VOUT1_D6_SLEWCONTROL
  [18] RGMII0_TXD2_INPUTENABLE rw
    values as CTRL_CORE_PAD_VOUT1_D6.VOUT1_D6_INPUTENABLE
  [17] RGMII0_TXD2_PULLTYPESELECT rw
    values as CTRL_CORE_PAD_VOUT1_D6.VOUT1_D6_PULLTYPESELECT
  [16] RGMII0_TXD2_PULLUDENABLE rw
    values as CTRL_CORE_PAD_VOUT1_D6.VOUT1_D6_PULLUDENABLE
  [8] RGMII0_TXD2_MODESELECT rw — Selects between the Default IO Timing Mode and a Virtual or Manual IO Timing Mode. Refer to the device Data Manual for definition of the required settings for a given mode of operation. When this bit is 0b1, a Virtual IO Timing Mode can be selected via the DELAYMODE field of this register, as described in, Virtual IO Timing Modes. Manual IO Timing Modes are selected via the procedure described in , Manual IO Timing Modes.
    values as CTRL_CORE_PAD_VOUT1_D6.VOUT1_D6_MODESELECT
  [7:4] RGMII0_TXD2_DELAYMODE rw — This bit field selects the Virtual Timing Mode used when the MODESELECT bit is set to 0b1. See, Virtual IO Timing Modes for details.
  [3:0] RGMII0_TXD2_MUXMODE rw
    0=RGMII0_TXD2; 1=RMII0_RXER; 3=MII0_RXER; 4=VIN2A_HSYNC0; 5=VIN4B_HSYNC1; 7=SPI4_D1; 8=UART4_TXD; 11=PR1_MII0_RXER; 12=PR2_PRU1_GPI8; 13=PR2_PRU1_GPO8; 14=GPIO5_23; 15=DRIVER OFF
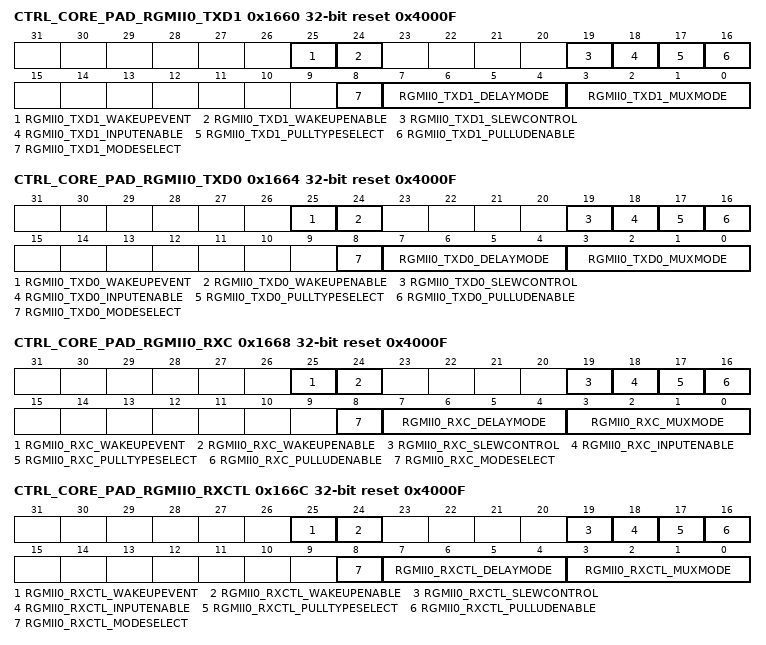
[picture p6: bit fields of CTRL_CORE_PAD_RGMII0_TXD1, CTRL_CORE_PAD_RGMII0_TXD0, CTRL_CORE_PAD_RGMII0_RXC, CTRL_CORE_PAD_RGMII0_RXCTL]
0x1660 CTRL_CORE_PAD_RGMII0_TXD1 reset 0x4000F
  [25] RGMII0_TXD1_WAKEUPEVENT ro
    values as CTRL_CORE_PAD_VOUT1_D6.VOUT1_D6_WAKEUPEVENT
  [24] RGMII0_TXD1_WAKEUPENABLE rw
    0=DISABLE (Wakeup is disabled); 1=ENABLE (Wakeup is enabled)
  [19] RGMII0_TXD1_SLEWCONTROL rw
    values as CTRL_CORE_PAD_VOUT1_D6.VOUT1_D6_SLEWCONTROL
  [18] RGMII0_TXD1_INPUTENABLE rw
    values as CTRL_CORE_PAD_VOUT1_D6.VOUT1_D6_INPUTENABLE
  [17] RGMII0_TXD1_PULLTYPESELECT rw
    values as CTRL_CORE_PAD_VOUT1_D6.VOUT1_D6_PULLTYPESELECT
  [16] RGMII0_TXD1_PULLUDENABLE rw
    values as CTRL_CORE_PAD_VOUT1_D6.VOUT1_D6_PULLUDENABLE
  [8] RGMII0_TXD1_MODESELECT rw — Selects between the Default IO Timing Mode and a Virtual or Manual IO Timing Mode. Refer to the device Data Manual for definition of the required settings for a given mode of operation. When this bit is 0b1, a Virtual IO Timing Mode can be selected via the DELAYMODE field of this register, as described in, Virtual IO Timing Modes. Manual IO Timing Modes are selected via the procedure described in , Manual IO Timing Modes.
    values as CTRL_CORE_PAD_VOUT1_D6.VOUT1_D6_MODESELECT
  [7:4] RGMII0_TXD1_DELAYMODE rw — This bit field selects the Virtual Timing Mode used when the MODESELECT bit is set to 0b1. See, Virtual IO Timing Modes for details.
  [3:0] RGMII0_TXD1_MUXMODE rw
    0=RGMII0_TXD1; 1=RMII0_RXD1; 3=MII0_RXD1; 4=VIN2A_VSYNC0; 5=VIN4B_VSYNC1; 7=SPI4_D0; 8=UART4_CTSN; 11=PR1_MII0_RXD1; 12=PR2_PRU1_GPI9; 13=PR2_PRU1_GPO9; 14=GPIO5_24; 15=DRIVER OFF
0x1664 CTRL_CORE_PAD_RGMII0_TXD0 reset 0x4000F
  [25] RGMII0_TXD0_WAKEUPEVENT ro
    values as CTRL_CORE_PAD_VOUT1_D6.VOUT1_D6_WAKEUPEVENT
  [24] RGMII0_TXD0_WAKEUPENABLE rw
    0=DISABLE (Wakeup is disabled); 1=ENABLE (Wakeup is enabled)
  [19] RGMII0_TXD0_SLEWCONTROL rw
    values as CTRL_CORE_PAD_VOUT1_D6.VOUT1_D6_SLEWCONTROL
  [18] RGMII0_TXD0_INPUTENABLE rw
    values as CTRL_CORE_PAD_VOUT1_D6.VOUT1_D6_INPUTENABLE
  [17] RGMII0_TXD0_PULLTYPESELECT rw
    values as CTRL_CORE_PAD_VOUT1_D6.VOUT1_D6_PULLTYPESELECT
  [16] RGMII0_TXD0_PULLUDENABLE rw
    values as CTRL_CORE_PAD_VOUT1_D6.VOUT1_D6_PULLUDENABLE
  [8] RGMII0_TXD0_MODESELECT rw — Selects between the Default IO Timing Mode and a Virtual or Manual IO Timing Mode. Refer to the device Data Manual for definition of the required settings for a given mode of operation. When this bit is 0b1, a Virtual IO Timing Mode can be selected via the DELAYMODE field of this register, as described in, Virtual IO Timing Modes. Manual IO Timing Modes are selected via the procedure described in , Manual IO Timing Modes.
    values as CTRL_CORE_PAD_VOUT1_D6.VOUT1_D6_MODESELECT
  [7:4] RGMII0_TXD0_DELAYMODE rw — This bit field selects the Virtual Timing Mode used when the MODESELECT bit is set to 0b1. See, Virtual IO Timing Modes for details.
  [3:0] RGMII0_TXD0_MUXMODE rw
    0=RGMII0_TXD0; 1=RMII0_RXD0; 3=MII0_RXD0; 4=VIN2A_D10; 7=SPI4_CS0; 8=UART4_RTSN; 11=PR1_MII0_RXD0; 12=PR2_PRU1_GPI10; 13=PR2_PRU1_GPO10; 14=GPIO5_25; 15=DRIVER OFF
0x1668 CTRL_CORE_PAD_RGMII0_RXC reset 0x4000F
  [25] RGMII0_RXC_WAKEUPEVENT ro
    values as CTRL_CORE_PAD_VOUT1_D6.VOUT1_D6_WAKEUPEVENT
  [24] RGMII0_RXC_WAKEUPENABLE rw
    0=DISABLE (Wakeup is disabled); 1=ENABLE (Wakeup is enabled)
  [19] RGMII0_RXC_SLEWCONTROL rw
    values as CTRL_CORE_PAD_VOUT1_D6.VOUT1_D6_SLEWCONTROL
  [18] RGMII0_RXC_INPUTENABLE rw
    values as CTRL_CORE_PAD_VOUT1_D6.VOUT1_D6_INPUTENABLE
  [17] RGMII0_RXC_PULLTYPESELECT rw
    values as CTRL_CORE_PAD_VOUT1_D6.VOUT1_D6_PULLTYPESELECT
  [16] RGMII0_RXC_PULLUDENABLE rw
    values as CTRL_CORE_PAD_VOUT1_D6.VOUT1_D6_PULLUDENABLE
  [8] RGMII0_RXC_MODESELECT rw — Selects between the Default IO Timing Mode and a Virtual or Manual IO Timing Mode. Refer to the device Data Manual for definition of the required settings for a given mode of operation. When this bit is 0b1, a Virtual IO Timing Mode can be selected via the DELAYMODE field of this register, as described in, Virtual IO Timing Modes. Manual IO Timing Modes are selected via the procedure described in , Manual IO Timing Modes.
    values as CTRL_CORE_PAD_VOUT1_D6.VOUT1_D6_MODESELECT
  [7:4] RGMII0_RXC_DELAYMODE rw — This bit field selects the Virtual Timing Mode used when the MODESELECT bit is set to 0b1. See, Virtual IO Timing Modes for details.
  [3:0] RGMII0_RXC_MUXMODE rw
    0=RGMII0_RXC; 2=RMII1_TXEN; 3=MII0_TXCLK; 4=VIN2A_D5; 5=VIN4B_D5; 11=PR1_MII_MT0_CLK; 12=PR2_PRU1_GPI11; 13=PR2_PRU1_GPO11; 14=GPIO5_26; 15=DRIVER OFF
0x166C CTRL_CORE_PAD_RGMII0_RXCTL reset 0x4000F
  [25] RGMII0_RXCTL_WAKEUPEVENT ro
    values as CTRL_CORE_PAD_VOUT1_D6.VOUT1_D6_WAKEUPEVENT
  [24] RGMII0_RXCTL_WAKEUPENABLE rw
    0=DISABLE (Wakeup is disabled); 1=ENABLE (Wakeup is enabled)
  [19] RGMII0_RXCTL_SLEWCONTROL rw
    values as CTRL_CORE_PAD_VOUT1_D6.VOUT1_D6_SLEWCONTROL
  [18] RGMII0_RXCTL_INPUTENABLE rw
    values as CTRL_CORE_PAD_VOUT1_D6.VOUT1_D6_INPUTENABLE
  [17] RGMII0_RXCTL_PULLTYPESELECT rw
    values as CTRL_CORE_PAD_VOUT1_D6.VOUT1_D6_PULLTYPESELECT
  [16] RGMII0_RXCTL_PULLUDENABLE rw
    values as CTRL_CORE_PAD_VOUT1_D6.VOUT1_D6_PULLUDENABLE
  [8] RGMII0_RXCTL_MODESELECT rw — Selects between the Default IO Timing Mode and a Virtual or Manual IO Timing Mode. Refer to the device Data Manual for definition of the required settings for a given mode of operation. When this bit is 0b1, a Virtual IO Timing Mode can be selected via the DELAYMODE field of this register, as described in, Virtual IO Timing Modes. Manual IO Timing Modes are selected via the procedure described in , Manual IO Timing Modes.
    values as CTRL_CORE_PAD_VOUT1_D6.VOUT1_D6_MODESELECT
  [7:4] RGMII0_RXCTL_DELAYMODE rw — This bit field selects the Virtual Timing Mode used when the MODESELECT bit is set to 0b1. See, Virtual IO Timing Modes for details.
  [3:0] RGMII0_RXCTL_MUXMODE rw
    0=RGMII0_RXCTL; 2=RMII1_TXD1; 3=MII0_TXD3; 4=VIN2A_D6; 5=VIN4B_D6; 11=PR1_MII0_TXD3; 12=PR2_PRU1_GPI12; 13=PR2_PRU1_GPO12; 14=GPIO5_27; 15=DRIVER OFF
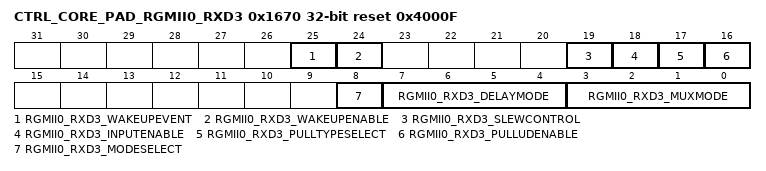
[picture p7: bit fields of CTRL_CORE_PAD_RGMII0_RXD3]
0x1670 CTRL_CORE_PAD_RGMII0_RXD3 reset 0x4000F
  [25] RGMII0_RXD3_WAKEUPEVENT ro
    values as CTRL_CORE_PAD_VOUT1_D6.VOUT1_D6_WAKEUPEVENT
  [24] RGMII0_RXD3_WAKEUPENABLE rw
    0=DISABLE (Wakeup is disabled); 1=ENABLE (Wakeup is enabled)
  [19] RGMII0_RXD3_SLEWCONTROL rw
    values as CTRL_CORE_PAD_VOUT1_D6.VOUT1_D6_SLEWCONTROL
  [18] RGMII0_RXD3_INPUTENABLE rw
    values as CTRL_CORE_PAD_VOUT1_D6.VOUT1_D6_INPUTENABLE
  [17] RGMII0_RXD3_PULLTYPESELECT rw
    values as CTRL_CORE_PAD_VOUT1_D6.VOUT1_D6_PULLTYPESELECT
  [16] RGMII0_RXD3_PULLUDENABLE rw
    values as CTRL_CORE_PAD_VOUT1_D6.VOUT1_D6_PULLUDENABLE
  [8] RGMII0_RXD3_MODESELECT rw — Selects between the Default IO Timing Mode and a Virtual or Manual IO Timing Mode. Refer to the device Data Manual for definition of the required settings for a given mode of operation. When this bit is 0b1, a Virtual IO Timing Mode can be selected via the DELAYMODE field of this register, as described in, Virtual IO Timing Modes. Manual IO Timing Modes are selected via the procedure described in , Manual IO Timing Modes.
    values as CTRL_CORE_PAD_VOUT1_D6.VOUT1_D6_MODESELECT
  [7:4] RGMII0_RXD3_DELAYMODE rw — This bit field selects the Virtual Timing Mode used when the MODESELECT bit is set to 0b1. See, Virtual IO Timing Modes for details.
  [3:0] RGMII0_RXD3_MUXMODE rw
    0=RGMII0_RXD3; 2=RMII1_TXD0; 3=MII0_TXD2; 4=VIN2A_D7; 5=VIN4B_D7; 11=PR1_MII0_TXD2; 12=PR2_PRU1_GPI13; 13=PR2_PRU1_GPO13; 14=GPIO5_28; 15=DRIVER OFF
